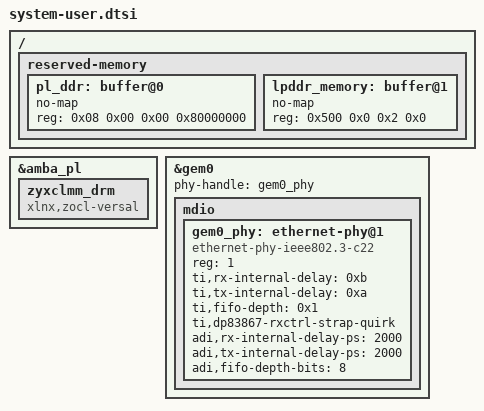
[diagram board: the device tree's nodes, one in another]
// SPDX-License-Identifier: MIT
// Copyright (C) 2025-2026, Opsero Electronic Design Inc.  All rights reserved.

/*
 * SoC-side board fixups for vek280 (Versal), layered on top of the
 * gen-machineconf / lopper-generated Linux device tree (which already carries
 * the PS config and the design's PL hardware from the XSA). Scoped to the Linux
 * domain by device-tree.bbappend. Ported from the Ethernet FMC Max AXI Ethernet PetaLinux BSP.
 */

/ {

reserved-memory {
        #address-cells = <2>;
        #size-cells = <2>;
        ranges;
        pl_ddr: buffer@0
        {
        no-map;
        reg = <0x08 0x00 0x00 0x80000000>;
        };

        lpddr_memory: buffer@1
        {
        no-map;
        reg = <0x500 0x0 0x2 0x0>;
        };

};


};

&amba_pl {
        zyxclmm_drm {
                compatible = "xlnx,zocl-versal";
        };
};

/* Board RJ45 (GEM0 = u198 PHY; GEM1 is not used on this board): the SDT
 * flow does not describe the board-level PHY, so Linux falls back to the
 * Generic PHY driver and the RGMII clock delays are never programmed -
 * the link negotiates 1G but passes no packets.
 * The PHY at MDIO addr 1 differs by board revision (official dts):
 *   versal-vek280-revA.dts: TI DP83867, RX 3.00 ns (0xb) / TX 2.75 ns (0xa)
 *   versal-vek280-revB.dts: ADI ADIN1300, RX/TX 2000 ps, FIFO 8 bits
 * so the node carries NO PHY-ID compatible: phylib reads the ID registers
 * and binds whichever driver matches (both are built in), and each driver
 * only reads its own ti,* / adi,* properties. reset-gpios omitted because
 * the SDT device tree does not define the gpio1 label - the PHY powers up
 * out of reset from straps. NOT yet verified on a VEK280.
 * No fixed MAC: the MAC stays random per boot (add a local-mac-address
 * property to pin one).
 */
&gem0 {
	phy-handle = <&gem0_phy>;
	mdio {
		#address-cells = <1>;
		#size-cells = <0>;
		gem0_phy: ethernet-phy@1 {
			compatible = "ethernet-phy-ieee802.3-c22";
			reg = <1>;
			ti,rx-internal-delay = <0xb>;
			ti,tx-internal-delay = <0xa>;
			ti,fifo-depth = <0x1>;
			ti,dp83867-rxctrl-strap-quirk;
			adi,rx-internal-delay-ps = <2000>;
			adi,tx-internal-delay-ps = <2000>;
			adi,fifo-depth-bits = <8>;
		};
	};
};
